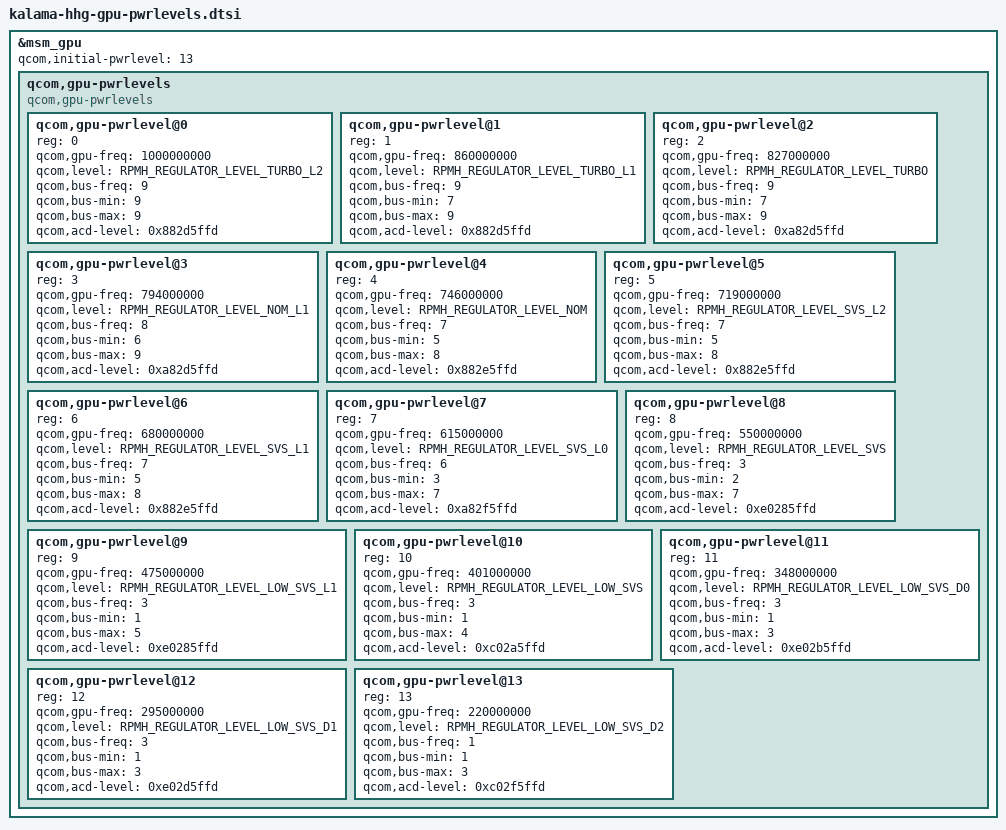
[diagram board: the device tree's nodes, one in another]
&msm_gpu {
	qcom,initial-pwrlevel = <13>;

	/* Power levels */
	qcom,gpu-pwrlevels {
		#address-cells = <1>;
		#size-cells = <0>;

		compatible = "qcom,gpu-pwrlevels";

		qcom,gpu-pwrlevel@0 {
			reg = <0>;
			qcom,gpu-freq = <1000000000>;
			qcom,level = <RPMH_REGULATOR_LEVEL_TURBO_L2>;

			qcom,bus-freq = <9>;
			qcom,bus-min = <9>;
			qcom,bus-max = <9>;

			qcom,acd-level = <0x882d5ffd>;
		};

		qcom,gpu-pwrlevel@1 {
			reg = <1>;
			qcom,gpu-freq = <860000000>;
			qcom,level = <RPMH_REGULATOR_LEVEL_TURBO_L1>;

			qcom,bus-freq = <9>;
			qcom,bus-min = <7>;
			qcom,bus-max = <9>;

			qcom,acd-level = <0x882d5ffd>;
		};

		qcom,gpu-pwrlevel@2 {
			reg = <2>;
			qcom,gpu-freq = <827000000>;
			qcom,level = <RPMH_REGULATOR_LEVEL_TURBO>;

			qcom,bus-freq = <9>;
			qcom,bus-min = <7>;
			qcom,bus-max = <9>;

			qcom,acd-level = <0xa82d5ffd>;
		};

		qcom,gpu-pwrlevel@3 {
			reg = <3>;
			qcom,gpu-freq = <794000000>;
			qcom,level = <RPMH_REGULATOR_LEVEL_NOM_L1>;

			qcom,bus-freq = <8>;
			qcom,bus-min = <6>;
			qcom,bus-max = <9>;

			qcom,acd-level = <0xa82d5ffd>;
		};

		qcom,gpu-pwrlevel@4 {
			reg = <4>;
			qcom,gpu-freq = <746000000>;
			qcom,level = <RPMH_REGULATOR_LEVEL_NOM>;

			qcom,bus-freq = <7>;
			qcom,bus-min = <5>;
			qcom,bus-max = <8>;

			qcom,acd-level = <0x882e5ffd>;
		};

		qcom,gpu-pwrlevel@5 {
			reg = <5>;
			qcom,gpu-freq = <719000000>;
			qcom,level = <RPMH_REGULATOR_LEVEL_SVS_L2>;

			qcom,bus-freq = <7>;
			qcom,bus-min = <5>;
			qcom,bus-max = <8>;

			qcom,acd-level = <0x882e5ffd>;
		};

		qcom,gpu-pwrlevel@6 {
			reg = <6>;
			qcom,gpu-freq = <680000000>;
			qcom,level = <RPMH_REGULATOR_LEVEL_SVS_L1>;

			qcom,bus-freq = <7>;
			qcom,bus-min = <5>;
			qcom,bus-max = <8>;

			qcom,acd-level = <0x882e5ffd>;
		};

		qcom,gpu-pwrlevel@7 {
			reg = <7>;
			qcom,gpu-freq = <615000000>;
			qcom,level = <RPMH_REGULATOR_LEVEL_SVS_L0>;

			qcom,bus-freq = <6>;
			qcom,bus-min = <3>;
			qcom,bus-max = <7>;

			qcom,acd-level = <0xa82f5ffd>;
		};

		qcom,gpu-pwrlevel@8 {
			reg = <8>;
			qcom,gpu-freq = <550000000>;
			qcom,level = <RPMH_REGULATOR_LEVEL_SVS>;

			qcom,bus-freq = <3>;
			qcom,bus-min = <2>;
			qcom,bus-max = <7>;

			qcom,acd-level = <0xe0285ffd>;
		};

		qcom,gpu-pwrlevel@9 {
			reg = <9>;
			qcom,gpu-freq = <475000000>;
			qcom,level = <RPMH_REGULATOR_LEVEL_LOW_SVS_L1>;

			qcom,bus-freq = <3>;
			qcom,bus-min = <1>;
			qcom,bus-max = <5>;

			qcom,acd-level = <0xe0285ffd>;
		};

		qcom,gpu-pwrlevel@10 {
			reg = <10>;
			qcom,gpu-freq = <401000000>;
			qcom,level = <RPMH_REGULATOR_LEVEL_LOW_SVS>;

			qcom,bus-freq = <3>;
			qcom,bus-min = <1>;
			qcom,bus-max = <4>;

			qcom,acd-level = <0xc02a5ffd>;
		};

		qcom,gpu-pwrlevel@11 {
			reg = <11>;
			qcom,gpu-freq = <348000000>;
			qcom,level = <RPMH_REGULATOR_LEVEL_LOW_SVS_D0>;

			qcom,bus-freq = <3>;
			qcom,bus-min = <1>;
			qcom,bus-max = <3>;

			qcom,acd-level = <0xe02b5ffd>;
		};

		qcom,gpu-pwrlevel@12 {
			reg = <12>;
			qcom,gpu-freq = <295000000>;
			qcom,level = <RPMH_REGULATOR_LEVEL_LOW_SVS_D1>;

			qcom,bus-freq = <3>;
			qcom,bus-min = <1>;
			qcom,bus-max = <3>;

			qcom,acd-level = <0xe02d5ffd>;
		};

		qcom,gpu-pwrlevel@13 {
			reg = <13>;
			qcom,gpu-freq = <220000000>;
			qcom,level = <RPMH_REGULATOR_LEVEL_LOW_SVS_D2>;

			qcom,bus-freq = <1>;
			qcom,bus-min = <1>;
			qcom,bus-max = <3>;

			qcom,acd-level = <0xc02f5ffd>;
		};
	};
};

